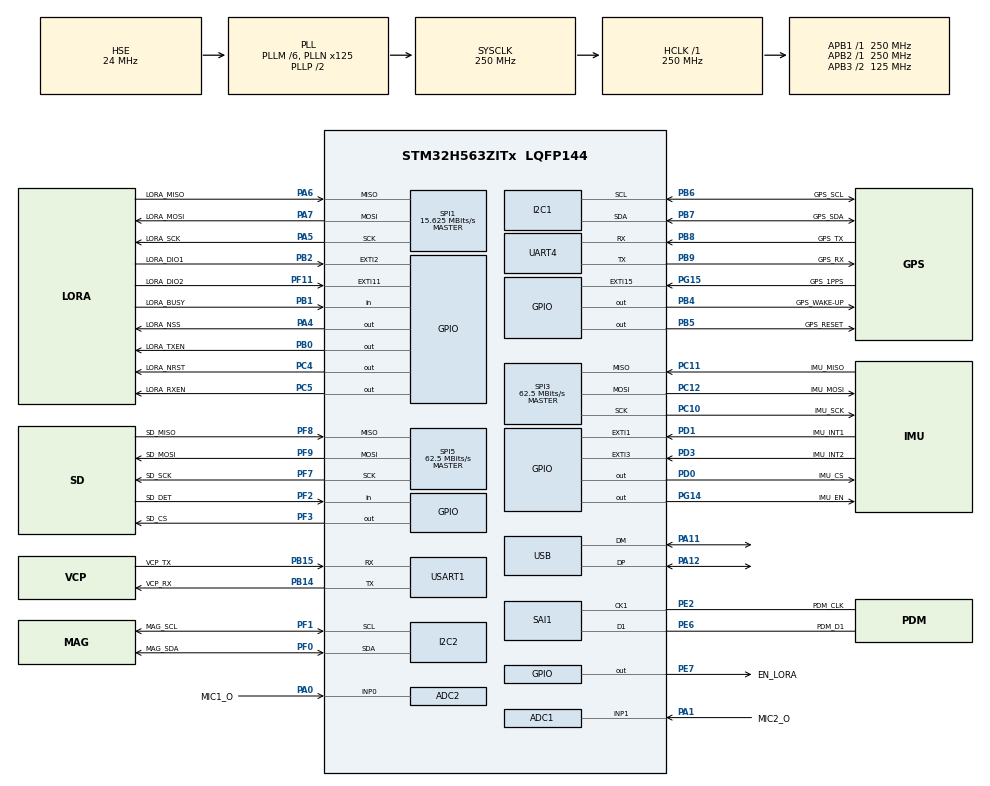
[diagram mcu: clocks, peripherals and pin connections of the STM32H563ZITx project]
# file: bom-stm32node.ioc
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ADC1.Channel-0\#ChannelRegularConversion=ADC_CHANNEL_1
ADC1.MonitoredBy-0\#ChannelRegularConversion=__NULL
ADC1.NbrOfConversionFlag=1
ADC1.OffsetNumber-0\#ChannelRegularConversion=ADC_OFFSET_NONE
ADC1.Rank-0\#ChannelRegularConversion=1
ADC1.SamplingTime-0\#ChannelRegularConversion=ADC_SAMPLETIME_2CYCLES_5
ADC1.master=1
ADC2.Channel-2\#ChannelRegularConversion=ADC_CHANNEL_0
ADC2.MonitoredBy-2\#ChannelRegularConversion=__NULL
ADC2.NbrOfConversionFlag=1
ADC2.OffsetNumber-2\#ChannelRegularConversion=ADC_OFFSET_NONE
ADC2.Rank-2\#ChannelRegularConversion=1
ADC2.SamplingTime-2\#ChannelRegularConversion=ADC_SAMPLETIME_2CYCLES_5
BOOTPATH.BootPathName=LEGACY
BOOTPATH.UserSelectedBootPath=LEGACY
CORTEX_M33_NS.userName=CORTEX_M33
I2C1.Timing=0x60808CD3
I2C2.Timing=0x60808CD3
Mcu.Family=STM32H5
Mcu.Name=STM32H563ZITx
Mcu.Package=LQFP144
NVIC.PriorityGroup=NVIC_PRIORITYGROUP_4
NVIC.USB_DRD_FS_IRQn=true\:0\:0\:false\:false\:true\:true\:true\:true
PA0.GPIO_Label=MIC1_O
PA0.Signal=ADCx_INP0
PA1.GPIO_Label=MIC2_O
PA1.Signal=ADCx_INP1
PA11.Mode=Device
PA11.Signal=USB_DM
PA12.Mode=Device
PA12.Signal=USB_DP
PA13(JTMS/SWDIO).Mode=Serial_Wire
PA13(JTMS/SWDIO).Signal=DEBUG_JTMS-SWDIO
PA14(JTCK/SWCLK).Mode=Serial_Wire
PA14(JTCK/SWCLK).Signal=DEBUG_JTCK-SWCLK
PA4.GPIO_Label=LORA_NSS
PA4.PinState=GPIO_PIN_SET
PA4.Signal=GPIO_Output
PA5.GPIO_Label=LORA_SCK
PA5.Mode=Full_Duplex_Master
PA5.Signal=SPI1_SCK
PA6.GPIO_Label=LORA_MISO
PA6.Mode=Full_Duplex_Master
PA6.Signal=SPI1_MISO
PA7.GPIO_Label=LORA_MOSI
PA7.Mode=Full_Duplex_Master
PA7.Signal=SPI1_MOSI
PB0.GPIO_Label=LORA_TXEN
PB0.Signal=GPIO_Output
PB1.GPIO_Label=LORA_BUSY
PB1.Signal=GPIO_Input
PB14.GPIO_Label=VCP_RX
PB14.Mode=Asynchronous
PB14.Signal=USART1_TX
PB15.GPIO_Label=VCP_TX
PB15.Mode=Asynchronous
PB15.Signal=USART1_RX
PB2.GPIO_Label=LORA_DIO1
PB2.Signal=GPXTI2
PB4(NJTRST).GPIO_Label=GPS_WAKE-UP
PB4(NJTRST).Signal=GPIO_Output
PB5.GPIO_Label=GPS_RESET
PB5.PinState=GPIO_PIN_SET
PB5.Signal=GPIO_Output
PB6.GPIO_Label=GPS_SCL
PB6.Mode=I2C
PB6.Signal=I2C1_SCL
PB7.GPIO_Label=GPS_SDA
PB7.Mode=I2C
PB7.Signal=I2C1_SDA
PB8.GPIO_Label=GPS_TX
PB8.Mode=Asynchronous
PB8.Signal=UART4_RX
PB9.GPIO_Label=GPS_RX
PB9.Mode=Asynchronous
PB9.Signal=UART4_TX
PC10.GPIO_Label=IMU_SCK
PC10.Mode=Full_Duplex_Master
PC10.Signal=SPI3_SCK
PC11.GPIO_Label=IMU_MISO
PC11.Mode=Full_Duplex_Master
PC11.Signal=SPI3_MISO
PC12.GPIO_Label=IMU_MOSI
PC12.Mode=Full_Duplex_Master
PC12.Signal=SPI3_MOSI
PC4.GPIO_Label=LORA_NRST
PC4.Signal=GPIO_Output
PC5.GPIO_Label=LORA_RXEN
PC5.Signal=GPIO_Output
PD0.GPIO_Label=IMU_CS
PD0.Signal=GPIO_Output
PD1.GPIO_Label=IMU_INT1
PD1.Signal=GPXTI1
PD3.GPIO_Label=IMU_INT2
PD3.Signal=GPXTI3
PE2.GPIO_Label=PDM_CLK
PE2.Mode=PDM_Master_Mode_CK1
PE2.Signal=SAI1_CK1
PE4.GPIO_Label=PDM_D2
PE4.Signal=SAI1_D2
PE6.GPIO_Label=PDM_D1
PE6.Mode=PDM_Master_Mode_CK1
PE6.Signal=SAI1_D1
PE7.GPIO_Label=EN_LORA
PE7.Signal=GPIO_Output
PF0.GPIO_Label=MAG_SDA
PF0.Mode=I2C
PF0.Signal=I2C2_SDA
PF1.GPIO_Label=MAG_SCL
PF1.Mode=I2C
PF1.Signal=I2C2_SCL
PF10.GPIO_Label=PDM_D3
PF10.Signal=SAI1_D3
PF11.GPIO_Label=LORA_DIO2
PF11.Signal=GPXTI11
PF2.GPIO_Label=SD_DET
PF2.Signal=GPIO_Input
PF3.GPIO_Label=SD_CS
PF3.Signal=GPIO_Output
PF7.GPIO_Label=SD_SCK
PF7.Mode=Full_Duplex_Master
PF7.Signal=SPI5_SCK
PF8.GPIO_Label=SD_MISO
PF8.Mode=Full_Duplex_Master
PF8.Signal=SPI5_MISO
PF9.GPIO_Label=SD_MOSI
PF9.Mode=Full_Duplex_Master
PF9.Signal=SPI5_MOSI
PG14.GPIO_Label=IMU_EN
PG14.Signal=GPIO_Output
PG15.GPIO_Label=GPS_1PPS
PG15.Signal=GPXTI15
PH0-OSC_IN(PH0).Mode=HSE-External-Oscillator
PH0-OSC_IN(PH0).Signal=RCC_OSC_IN
PH1-OSC_OUT(PH1).Mode=HSE-External-Oscillator
PH1-OSC_OUT(PH1).Signal=RCC_OSC_OUT
ProjectManager.HeapSize=0x200
ProjectManager.StackSize=0x400
ProjectManager.TargetToolchain=CMake
RCC.ADCFreq_Value=250000000
RCC.AHBFreq_Value=250000000
RCC.APB1Freq_Value=250000000
RCC.APB1TimFreq_Value=250000000
RCC.APB2Freq_Value=250000000
RCC.APB2TimFreq_Value=250000000
RCC.APB3CLKDivider=RCC_HCLK_DIV2
RCC.APB3Freq_Value=125000000
RCC.CSI_VALUE=4000000
RCC.CortexFreq_Value=250000000
RCC.EPOD_VALUE=24000000
RCC.HCLKFreq_Value=250000000
RCC.HSE_VALUE=24000000
RCC.HSI48_VALUE=48000000
RCC.HSI_VALUE=64000000
RCC.LSE_VALUE=32768
RCC.LSIRC_VALUE=32000
RCC.PLL1Q=4
RCC.PLL2FRACN=131
RCC.PLL2N=86
RCC.PLL2P=28
RCC.PLL3FRACN=0
RCC.PLLFRACN=0
RCC.PLLM=6
RCC.PLLN=125
RCC.PLLSourceVirtual=RCC_PLL1_SOURCE_HSE
RCC.SYSCLKFreq_VALUE=250000000
RCC.SYSCLKSource=RCC_SYSCLKSOURCE_PLLCLK
RCC.USBFreq_Value=48000000
RCC.VCOOutputFreq_Value=500000000
SAI1.Activation=ENABLE
SAI1.AudioFrequency-PDM_Master_Mode_CK1=SAI_AUDIO_FREQUENCY_48K
SAI1.DataSize-PDM_Master_Mode_CK1=SAI_DATASIZE_16
SAI1.ErrorAudioFreq-PDM_Master_Mode_CK1=0.0 %
SAI1.FrameLength-PDM_Master_Mode_CK1=16
SAI1.Instance-PDM_Master_Mode_CK1=SAI$Index_Block_A
SAI1.MckOutput-PDM_Master_Mode_CK1=SAI_MCK_OUTPUT_DISABLE
SAI1.RealAudioFreq-PDM_Master_Mode_CK1=47.999 KHz
SAI1.SlotActive-PDM_Master_Mode_CK1=0x00000001
SAI1.VirtualMode-PDM_Master_Mode_CK1=VM_MASTER
SAI1.VirtualProtocol-PDM_Master_Mode_CK1=VM_PDM_PROTOCOL
SAI1.VirtualSlotActive-PDM_Master_Mode_CK1=SAI_SLOT_USERSETTING
SAI1.VirtualSlotActive0-PDM_Master_Mode_CK1=true
SH.ADCx_INP0.0=ADC2_INP0,IN0-Single-Ended
SH.ADCx_INP1.0=ADC1_INP1,IN1-Single-Ended
SPI1.BaudRatePrescaler=SPI_BAUDRATEPRESCALER_8
SPI1.CalculateBaudRate=15.625 MBits/s
SPI1.DataSize=SPI_DATASIZE_8BIT
SPI1.Direction=SPI_DIRECTION_2LINES
SPI1.Mode=SPI_MODE_MASTER
SPI1.VirtualNSS=VM_NSSSOFT
SPI1.VirtualType=VM_MASTER
SPI3.CalculateBaudRate=62.5 MBits/s
SPI3.Direction=SPI_DIRECTION_2LINES
SPI3.Mode=SPI_MODE_MASTER
SPI3.VirtualType=VM_MASTER
SPI5.CalculateBaudRate=62.5 MBits/s
SPI5.Direction=SPI_DIRECTION_2LINES
SPI5.Mode=SPI_MODE_MASTER
SPI5.VirtualType=VM_MASTER
USART1.VirtualMode-Asynchronous=VM_ASYNC
USB.VirtualMode=Device_Only
USBX.BSP.number=1
USBX.Core_System=1
USBX.USBD_CDCACM_EPIN_ADDR=2
USBX.USBD_CDCACM_EPOUT_ADDR=3
USBX.UX_DEVICE_CDC_ACM=1
USBX.UX_DEVICE_ENABLED_FS=1
USBX.UX_Device_Controller=1
USBX.UX_Device_CoreStack=1
USBX.UX_enabled_FS=1
USBX0.BSP.STBoard=false
USBX0.BSP.api=Unknown
USBX0.BSP.condition=\!DIE47A
USBX0.BSP.instance=USB
USBX0.BSP.ip=USB
USBX0.BSP.mode=Device_Only
USBX0.BSP.name=USB_Device
USBX0.BSP.solution=USB
VP_BOOTPATH_VS_BOOTPATH.Mode=BP_Activate
VP_CORTEX_M33_NS_VS_Hclk.Mode=Hclk_Mode
VP_MEMORYMAP_VS_MEMORYMAP.Mode=CurAppReg
VP_PWR_VS_LPOM.Mode=PowerOptimisation
VP_PWR_VS_SECSignals.Mode=Security/Privilege
VP_RCC_USB.Mode=CRS SYNC Source USB
VP_USBX_Core_System.Mode=Core_System
VP_USBX_UX\ Device\ CDC\ ACM\ Class_FS.Mode=UX_Device_class_CDC_ACM_FS_HS
VP_USBX_UX\ Device\ Controller_FS.Mode=UX_Device_Controller_FS
VP_USBX_UX\ Device\ CoreStack_FS.Mode=UX_Device_CoreStack
board=custom

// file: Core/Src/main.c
/* USER CODE BEGIN Header */
/**
  ******************************************************************************
  * @file           : main.c
  * @brief          : Main program body
  ******************************************************************************
  * @attention
  *
  * Copyright (c) 2026 STMicroelectronics.
  * All rights reserved.
  *
  * This software is licensed under terms that can be found in the LICENSE file
  * in the root directory of this software component.
  * If no LICENSE file comes with this software, it is provided AS-IS.
  *
  ******************************************************************************
  */
/* USER CODE END Header */
#include "main.h"
#include "adc.h"
#include "i2c.h"
#include "sai.h"
#include "spi.h"
#include "usart.h"
#include "usb.h"
#include "app_usbx.h"
#include "gpio.h"

/* USER CODE BEGIN Includes */
#include "usb_cli.h"
#include "radio.h"
/* USER CODE END Includes */

void SystemClock_Config(void);

int main(void)
{

  /* MCU Configuration--------------------------------------------------------*/

  /* Reset of all peripherals, Initializes the Flash interface and the Systick. */
  HAL_Init();

  /* Configure the system clock */
  SystemClock_Config();

  /* Initialize all configured peripherals */
  MX_GPIO_Init();
  MX_I2C1_Init();
  MX_SPI1_Init();
  MX_USB_PCD_Init();
  MX_I2C2_Init();
  MX_SAI1_Init();
  MX_SPI3_Init();
  MX_ADC1_Init();
  MX_ADC2_Init();
  MX_USART1_UART_Init();
  MX_UART4_Init();
  MX_SPI5_Init();
  MX_USBX_Init();
  /* USER CODE BEGIN 2 */
  /* The microphone (SAI1 + GPDMA, per docs/pdm-port-plan.md "CubeMX contract")
     is started on demand by the `stream` command (see pcm_stream.c), so there
     is nothing to start here. */

  /* SX1262 bring-up (SPI1 + EN_LORA/NRST/BUSY/DIO1, see App/radio/radio.h),
     BEFORE the USB pull-up goes live (usb_cli_start(), next): RadioLib's
     internal chip-detect retries the reset/SPI probe up to 10 times with a
     1 s standby-verify timeout each when no module answers, so radio_init()
     can block for several seconds. Doing that before usb_cli_start() means
     the host never sees the device on the bus mid-enumeration during that
     window - USB simply appears a few seconds later instead of an
     enumeration attempt timing out because nothing was servicing the USB
     stack. A radio failure itself is never fatal: the radio stays disabled
     and `radio status` over the CLI reports why. */
  (void)radio_init();

  /* USB CDC command console (endpoint PMA + PCD start + CLI, see usb_cli.c).
     BEFORE the instruction cache is enabled below: usb_cli_start() ->
     cli_init() -> link_service_init() reads the chip's factory UID
     (HAL_GetUIDw0()/w1()/w2(), App/link/link_service.c's derive_node_id()/
     derive_session_id() and App/link/boomlink_radio_port.c's PRNG seed -
     the only three call sites of those HAL functions anywhere in this
     firmware, all reached exactly once here, synchronously, and never
     again afterwards) from UID_BASE (0x08FFF800 - the STM32H563's OTP-style
     Flash-size/UID/package info block, not the flash array proper). Found
     by hardware bring-up: with the cache enabled first (as this file used
     to do), that read HardFaults - a precise BusFault at BFAR == UID_BASE,
     confirmed identical on two independently flashed boards, confirmed the
     address itself is valid and its data plausible by reading it directly
     over SWD (which bypasses the CPU and its cache entirely and succeeds).
     The CPU's own cached read is what faults, not the address - a burst
     line-fill transaction this info block's controller does not answer the
     same way a debug probe's single AHB-AP read does. Deferring the enable
     until after these three one-time reads sidesteps the mechanism
     entirely, whatever ST's cache implementation is actually doing
     underneath, without needing to disable/re-enable the cache around a
     read that never recurs. */
  usb_cli_start();

  /* Enable the instruction cache. The core runs code from flash at 250 MHz with
     5 wait states (FLASH_LATENCY_5); with the cache off, every instruction fetch
     stalls the CPU and the PDM->PCM DSP misses its 21.33 ms/ring-half real-time
     budget (~39 ms measured -> mic overrun). Cached it takes ~6 ms and fits.
     CubeMX leaves HAL_ICACHE_MODULE_ENABLED off in stm32h5xx_hal_conf.h, so the
     cache is driven directly here (keeps the CubeMX-owned conf untouched). The
     cache is invalidated on reset; wait for any pending invalidation, then
     enable it for the whole firmware.
     Deliberately AFTER usb_cli_start() (see that call's own comment for why -
     the UID-reading HardFault this ordering avoids), not before: the mic
     streaming path this cache exists for is only ever started later, on
     demand, by the `stream`/`streamtest` CLI commands the user issues once
     the board is already up and enumerated - comfortably after this point -
     so moving the enable this much later costs nothing the DSP budget above
     actually needs. */
  while ((ICACHE->SR & ICACHE_SR_BUSYF) != 0u)
  {
  }
  ICACHE->CR |= ICACHE_CR_EN;
  /* USER CODE END 2 */

  /* Infinite loop */
  while (1)
  {

    /* USER CODE BEGIN 3 */
    /* Drain the DIO1 event flag and drive RadioLib's TX/RX completion
       handling BEFORE usb_cli_process(): a `radio ping` dispatched from the
       CLI calls radio_send(), which changes the radio's mode. Servicing any
       event already pending from *before* this iteration first means a
       just-arrived RX-done can never be misread as the completion of a
       transmission the CLI is about to start in this same iteration (radio_
       send() also flushes defensively on its own - see radio.cpp - but
       draining here first is what keeps that from being load-bearing).
       Never runs from interrupt context - see boomlink.md section 6.2. Not
       serviced while a `stream`/`streamtest` command blocks the loop
       (documented limitation, same section). */
    radio_process();

    /* Service USB: enumeration, the CDC console, and PCM streaming. The
       `stream`/`streamtest` commands start the microphone on demand and run the
       whole transfer synchronously from here, so this loop has no separate
       mic_poll drain (a second consumer would steal ring halves). */
    usb_cli_process();
  }
  /* USER CODE END 3 */
}

void SystemClock_Config(void)
{
  RCC_OscInitTypeDef RCC_OscInitStruct = {0};
  RCC_ClkInitTypeDef RCC_ClkInitStruct = {0};
  RCC_CRSInitTypeDef RCC_CRSInitStruct = {0};

  /** Configure the main internal regulator output voltage
  */
  __HAL_PWR_VOLTAGESCALING_CONFIG(PWR_REGULATOR_VOLTAGE_SCALE0);

  while(!__HAL_PWR_GET_FLAG(PWR_FLAG_VOSRDY)) {}

  /** Initializes the RCC Oscillators according to the specified parameters
  * in the RCC_OscInitTypeDef structure.
  */
  RCC_OscInitStruct.OscillatorType = RCC_OSCILLATORTYPE_HSI48|RCC_OSCILLATORTYPE_HSE
                              |RCC_OSCILLATORTYPE_CSI;
  RCC_OscInitStruct.HSEState = RCC_HSE_ON;
  RCC_OscInitStruct.HSI48State = RCC_HSI48_ON;
  RCC_OscInitStruct.CSIState = RCC_CSI_ON;
  RCC_OscInitStruct.CSICalibrationValue = RCC_CSICALIBRATION_DEFAULT;
  RCC_OscInitStruct.PLL.PLLState = RCC_PLL_ON;
  RCC_OscInitStruct.PLL.PLLSource = RCC_PLL1_SOURCE_HSE;
  RCC_OscInitStruct.PLL.PLLM = 6;
  RCC_OscInitStruct.PLL.PLLN = 125;
  RCC_OscInitStruct.PLL.PLLP = 2;
  RCC_OscInitStruct.PLL.PLLQ = 4;
  RCC_OscInitStruct.PLL.PLLR = 2;
  RCC_OscInitStruct.PLL.PLLRGE = RCC_PLL1_VCIRANGE_2;
  RCC_OscInitStruct.PLL.PLLVCOSEL = RCC_PLL1_VCORANGE_WIDE;
  RCC_OscInitStruct.PLL.PLLFRACN = 0;
  if (HAL_RCC_OscConfig(&RCC_OscInitStruct) != HAL_OK)
  {
    Error_Handler();
  }

  /** Initializes the CPU, AHB and APB buses clocks
  */
  RCC_ClkInitStruct.ClockType = RCC_CLOCKTYPE_HCLK|RCC_CLOCKTYPE_SYSCLK
                              |RCC_CLOCKTYPE_PCLK1|RCC_CLOCKTYPE_PCLK2
                              |RCC_CLOCKTYPE_PCLK3;
  RCC_ClkInitStruct.SYSCLKSource = RCC_SYSCLKSOURCE_PLLCLK;
  RCC_ClkInitStruct.AHBCLKDivider = RCC_SYSCLK_DIV1;
  RCC_ClkInitStruct.APB1CLKDivider = RCC_HCLK_DIV1;
  RCC_ClkInitStruct.APB2CLKDivider = RCC_HCLK_DIV1;
  RCC_ClkInitStruct.APB3CLKDivider = RCC_HCLK_DIV2;

  if (HAL_RCC_ClockConfig(&RCC_ClkInitStruct, FLASH_LATENCY_5) != HAL_OK)
  {
    Error_Handler();
  }

  /** Enable the CRS APB clock
  */
  __HAL_RCC_CRS_CLK_ENABLE();

  /** Configures CRS
  */
  RCC_CRSInitStruct.Prescaler = RCC_CRS_SYNC_DIV1;
  RCC_CRSInitStruct.Source = RCC_CRS_SYNC_SOURCE_USB;
  RCC_CRSInitStruct.Polarity = RCC_CRS_SYNC_POLARITY_RISING;
  RCC_CRSInitStruct.ReloadValue = __HAL_RCC_CRS_RELOADVALUE_CALCULATE(48000000,1000);
  RCC_CRSInitStruct.ErrorLimitValue = 34;
  RCC_CRSInitStruct.HSI48CalibrationValue = 32;

  HAL_RCCEx_CRSConfig(&RCC_CRSInitStruct);

  /** Configure the programming delay
  */
  __HAL_FLASH_SET_PROGRAM_DELAY(FLASH_PROGRAMMING_DELAY_2);
}

void Error_Handler(void)
{
  __disable_irq();
  while (1)
  {
  }
}
